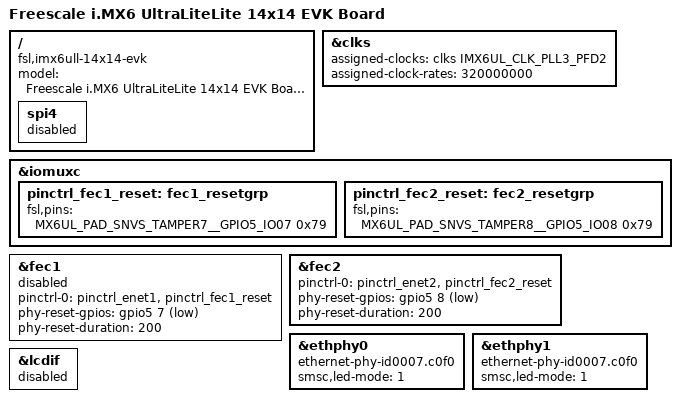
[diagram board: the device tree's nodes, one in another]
// SPDX-License-Identifier: (GPL-2.0 OR MIT)
//
// Copyright (C) 2016 Freescale Semiconductor, Inc.

/dts-v1/;

#include "imx6ull.dtsi"
#include "imx6ul-14x14-evk.dtsi"

/ {
	model = "Freescale i.MX6 UltraLiteLite 14x14 EVK Board";
	compatible = "fsl,imx6ull-14x14-evk", "fsl,imx6ull";
	    
	spi4 {
        status = "disabled";
    };
};

&clks {
	assigned-clocks = <&clks IMX6UL_CLK_PLL3_PFD2>;
	assigned-clock-rates = <320000000>;
};

&iomuxc {
    pinctrl_fec1_reset: fec1_resetgrp {
        fsl,pins = <
            MX6UL_PAD_SNVS_TAMPER7__GPIO5_IO07	0x79
        >;
    };

    pinctrl_fec2_reset: fec2_resetgrp {
        fsl,pins = <
            MX6UL_PAD_SNVS_TAMPER8__GPIO5_IO08	0x79
        >;
    };
};

&fec1 {
    pinctrl-0 = <&pinctrl_enet1
             &pinctrl_fec1_reset>;
    phy-reset-gpios = <&gpio5 7 GPIO_ACTIVE_LOW>;
    phy-reset-duration = <200>;
    status = "disabled";
};

&fec2 {
    pinctrl-0 = <&pinctrl_enet2
             &pinctrl_fec2_reset>;
    phy-reset-gpios = <&gpio5 8 GPIO_ACTIVE_LOW>;
    phy-reset-duration = <200>;
    status = "okay";
};

&ethphy0 {
    compatible = "ethernet-phy-id0007.c0f0";
    smsc,led-mode = <1>;
};

&ethphy1 {
    compatible = "ethernet-phy-id0007.c0f0";
    smsc,led-mode = <1>;
};

&lcdif {
	status = "disabled";
};
